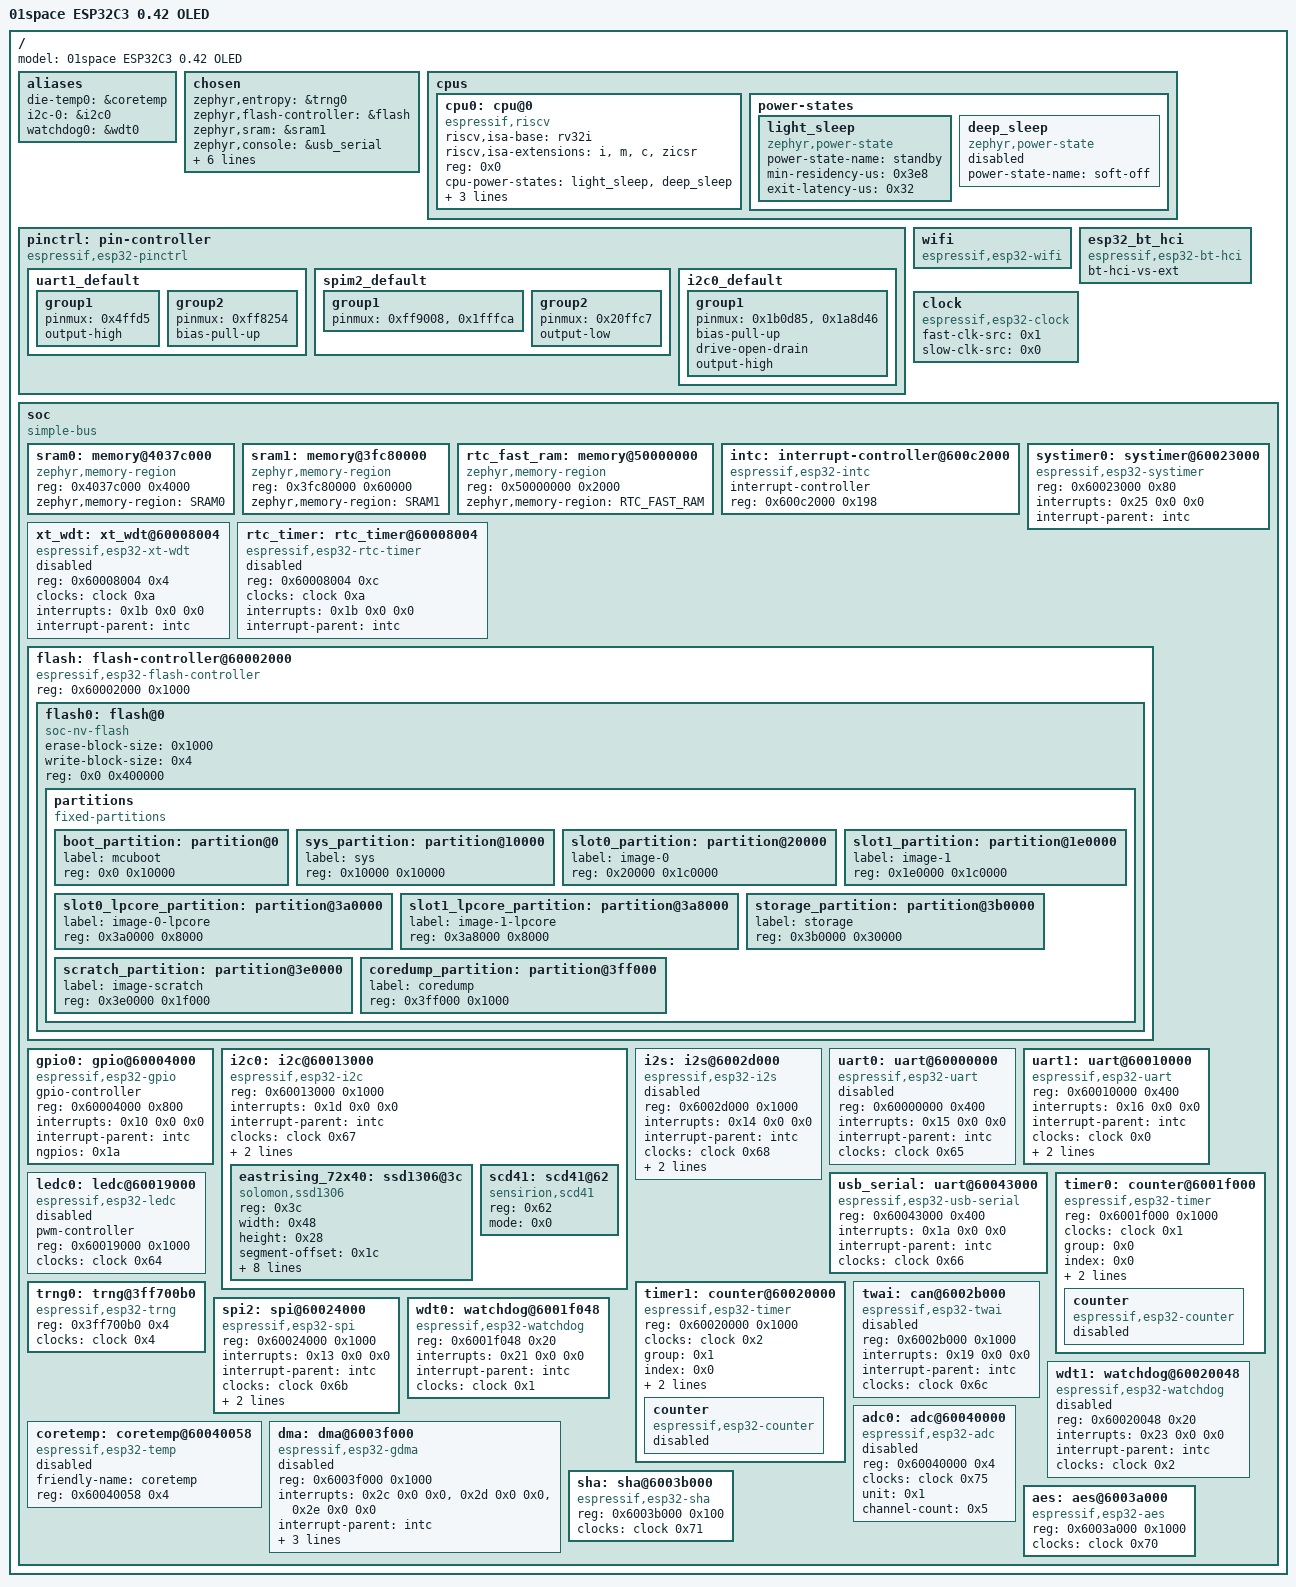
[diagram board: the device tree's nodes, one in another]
/dts-v1/;

/* node '/' defined in zephyr/dts/riscv/espressif/esp32c3/esp32c3_common.dtsi:15 */
/ {
	#address-cells = < 0x1 >;            /* in zephyr/dts/riscv/espressif/esp32c3/esp32c3_common.dtsi:16 */
	#size-cells = < 0x1 >;               /* in zephyr/dts/riscv/espressif/esp32c3/esp32c3_common.dtsi:17 */
	model = "01space ESP32C3 0.42 OLED"; /* in zephyr/boards/01space/esp32c3_042_oled/esp32c3_042_oled.dts:15 */

	/* node '/aliases' defined in zephyr/dts/riscv/espressif/esp32c3/esp32c3_common.dtsi:19 */
	aliases {
		die-temp0 = &coretemp; /* in zephyr/dts/riscv/espressif/esp32c3/esp32c3_common.dtsi:20 */
		i2c-0 = &i2c0;         /* in zephyr/boards/01space/esp32c3_042_oled/esp32c3_042_oled.dts:29 */
		watchdog0 = &wdt0;     /* in zephyr/boards/01space/esp32c3_042_oled/esp32c3_042_oled.dts:30 */
	};

	/* node '/chosen' defined in zephyr/dts/riscv/espressif/esp32c3/esp32c3_common.dtsi:23 */
	chosen {
		zephyr,entropy = &trng0;                  /* in zephyr/dts/riscv/espressif/esp32c3/esp32c3_common.dtsi:25 */
		zephyr,flash-controller = &flash;         /* in zephyr/dts/riscv/espressif/esp32c3/esp32c3_common.dtsi:26 */
		zephyr,sram = &sram1;                     /* in zephyr/boards/01space/esp32c3_042_oled/esp32c3_042_oled.dts:18 */
		zephyr,console = &usb_serial;             /* in zephyr/boards/01space/esp32c3_042_oled/esp32c3_042_oled.dts:19 */
		zephyr,shell-uart = &usb_serial;          /* in zephyr/boards/01space/esp32c3_042_oled/esp32c3_042_oled.dts:20 */
		zephyr,flash = &flash0;                   /* in zephyr/boards/01space/esp32c3_042_oled/esp32c3_042_oled.dts:21 */
		zephyr,code-partition = &slot0_partition; /* in zephyr/boards/01space/esp32c3_042_oled/esp32c3_042_oled.dts:22 */
		zephyr,canbus = &twai;                    /* in zephyr/boards/01space/esp32c3_042_oled/esp32c3_042_oled.dts:23 */
		zephyr,bt-hci = &esp32_bt_hci;            /* in zephyr/boards/01space/esp32c3_042_oled/esp32c3_042_oled.dts:24 */
		zephyr,display = &eastrising_72x40;       /* in zephyr/boards/01space/esp32c3_042_oled/esp32c3_042_oled.dts:25 */
	};

	/* node '/cpus' defined in zephyr/dts/riscv/espressif/esp32c3/esp32c3_common.dtsi:30 */
	cpus {
		#address-cells = < 0x1 >; /* in zephyr/dts/riscv/espressif/esp32c3/esp32c3_common.dtsi:31 */
		#size-cells = < 0x0 >;    /* in zephyr/dts/riscv/espressif/esp32c3/esp32c3_common.dtsi:32 */

		/* node '/cpus/cpu@0' defined in zephyr/dts/riscv/espressif/esp32c3/esp32c3_common.dtsi:34 */
		cpu0: cpu@0 {
			device_type = "cpu";                             /* in zephyr/dts/riscv/espressif/esp32c3/esp32c3_common.dtsi:35 */
			compatible = "espressif,riscv",
			             "riscv";                            /* in zephyr/dts/riscv/espressif/esp32c3/esp32c3_common.dtsi:36 */
			riscv,isa-base = "rv32i";                        /* in zephyr/dts/riscv/espressif/esp32c3/esp32c3_common.dtsi:37 */
			riscv,isa-extensions = "i",
			                       "m",
			                       "c",
			                       "zicsr";                  /* in zephyr/dts/riscv/espressif/esp32c3/esp32c3_common.dtsi:38 */
			reg = < 0x0 >;                                   /* in zephyr/dts/riscv/espressif/esp32c3/esp32c3_common.dtsi:39 */
			cpu-power-states = < &light_sleep &deep_sleep >; /* in zephyr/dts/riscv/espressif/esp32c3/esp32c3_common.dtsi:40 */
			clock-source = < 0x1 >;                          /* in zephyr/dts/riscv/espressif/esp32c3/esp32c3_common.dtsi:41 */
			clock-frequency = < 0x9896800 >;                 /* in zephyr/dts/riscv/espressif/esp32c3/esp32c3_common.dtsi:42 */
			xtal-freq = < 0x2625a00 >;                       /* in zephyr/dts/riscv/espressif/esp32c3/esp32c3_common.dtsi:43 */
		};

		/* node '/cpus/power-states' defined in zephyr/dts/riscv/espressif/esp32c3/esp32c3_common.dtsi:46 */
		power-states {

			/* node '/cpus/power-states/light_sleep' defined in zephyr/dts/riscv/espressif/esp32c3/esp32c3_common.dtsi:47 */
			light_sleep: light_sleep {
				compatible = "zephyr,power-state"; /* in zephyr/dts/riscv/espressif/esp32c3/esp32c3_common.dtsi:48 */
				power-state-name = "standby";      /* in zephyr/dts/riscv/espressif/esp32c3/esp32c3_common.dtsi:49 */
				min-residency-us = < 0x3e8 >;      /* in zephyr/dts/riscv/espressif/esp32c3/esp32c3_common.dtsi:50 */
				exit-latency-us = < 0x32 >;        /* in zephyr/dts/riscv/espressif/esp32c3/esp32c3_common.dtsi:51 */
				phandle = < 0x1 >;                 /* in zephyr/dts/riscv/espressif/esp32c3/esp32c3_common.dtsi:40 */
			};

			/* node '/cpus/power-states/deep_sleep' defined in zephyr/dts/riscv/espressif/esp32c3/esp32c3_common.dtsi:54 */
			deep_sleep: deep_sleep {
				compatible = "zephyr,power-state"; /* in zephyr/dts/riscv/espressif/esp32c3/esp32c3_common.dtsi:58 */
				power-state-name = "soft-off";     /* in zephyr/dts/riscv/espressif/esp32c3/esp32c3_common.dtsi:59 */
				status = "disabled";               /* in zephyr/dts/riscv/espressif/esp32c3/esp32c3_common.dtsi:60 */
				phandle = < 0x2 >;                 /* in zephyr/dts/riscv/espressif/esp32c3/esp32c3_common.dtsi:40 */
			};
		};
	};

	/* node '/pin-controller' defined in zephyr/dts/riscv/espressif/esp32c3/esp32c3_common.dtsi:65 */
	pinctrl: pin-controller {
		compatible = "espressif,esp32-pinctrl"; /* in zephyr/dts/riscv/espressif/esp32c3/esp32c3_common.dtsi:66 */
		status = "okay";                        /* in zephyr/dts/riscv/espressif/esp32c3/esp32c3_common.dtsi:67 */

		/* node '/pin-controller/uart1_default' defined in zephyr/boards/01space/esp32c3_042_oled/esp32c3_042_oled-pinctrl.dtsi:12 */
		uart1_default: uart1_default {
			phandle = < 0x7 >; /* in zephyr/boards/01space/esp32c3_042_oled/esp32c3_042_oled.dts:40 */

			/* node '/pin-controller/uart1_default/group1' defined in zephyr/boards/01space/esp32c3_042_oled/esp32c3_042_oled-pinctrl.dtsi:13 */
			group1 {
				pinmux = < 0x4ffd5 >; /* in zephyr/boards/01space/esp32c3_042_oled/esp32c3_042_oled-pinctrl.dtsi:14 */
				output-high;          /* in zephyr/boards/01space/esp32c3_042_oled/esp32c3_042_oled-pinctrl.dtsi:15 */
			};

			/* node '/pin-controller/uart1_default/group2' defined in zephyr/boards/01space/esp32c3_042_oled/esp32c3_042_oled-pinctrl.dtsi:18 */
			group2 {
				pinmux = < 0xff8254 >; /* in zephyr/boards/01space/esp32c3_042_oled/esp32c3_042_oled-pinctrl.dtsi:19 */
				bias-pull-up;          /* in zephyr/boards/01space/esp32c3_042_oled/esp32c3_042_oled-pinctrl.dtsi:20 */
			};
		};

		/* node '/pin-controller/spim2_default' defined in zephyr/boards/01space/esp32c3_042_oled/esp32c3_042_oled-pinctrl.dtsi:24 */
		spim2_default: spim2_default {
			phandle = < 0x8 >; /* in zephyr/boards/01space/esp32c3_042_oled/esp32c3_042_oled.dts:73 */

			/* node '/pin-controller/spim2_default/group1' defined in zephyr/boards/01space/esp32c3_042_oled/esp32c3_042_oled-pinctrl.dtsi:25 */
			group1 {
				pinmux = < 0xff9008 >,
				         < 0x1fffca >; /* in zephyr/boards/01space/esp32c3_042_oled/esp32c3_042_oled-pinctrl.dtsi:26 */
			};

			/* node '/pin-controller/spim2_default/group2' defined in zephyr/boards/01space/esp32c3_042_oled/esp32c3_042_oled-pinctrl.dtsi:30 */
			group2 {
				pinmux = < 0x20ffc7 >; /* in zephyr/boards/01space/esp32c3_042_oled/esp32c3_042_oled-pinctrl.dtsi:31 */
				output-low;            /* in zephyr/boards/01space/esp32c3_042_oled/esp32c3_042_oled-pinctrl.dtsi:32 */
			};
		};

		/* node '/pin-controller/i2c0_default' defined in zephyr/boards/01space/esp32c3_042_oled/esp32c3_042_oled-pinctrl.dtsi:36 */
		i2c0_default: i2c0_default {
			phandle = < 0x5 >; /* in zephyr/boards/01space/esp32c3_042_oled/esp32c3_042_oled.dts:47 */

			/* node '/pin-controller/i2c0_default/group1' defined in zephyr/boards/01space/esp32c3_042_oled/esp32c3_042_oled-pinctrl.dtsi:37 */
			group1 {
				pinmux = < 0x1b0d85 >,
				         < 0x1a8d46 >; /* in zephyr/boards/01space/esp32c3_042_oled/esp32c3_042_oled-pinctrl.dtsi:38 */
				bias-pull-up;          /* in zephyr/boards/01space/esp32c3_042_oled/esp32c3_042_oled-pinctrl.dtsi:40 */
				drive-open-drain;      /* in zephyr/boards/01space/esp32c3_042_oled/esp32c3_042_oled-pinctrl.dtsi:41 */
				output-high;           /* in zephyr/boards/01space/esp32c3_042_oled/esp32c3_042_oled-pinctrl.dtsi:42 */
			};
		};
	};

	/* node '/wifi' defined in zephyr/dts/riscv/espressif/esp32c3/esp32c3_common.dtsi:70 */
	wifi: wifi {
		compatible = "espressif,esp32-wifi"; /* in zephyr/dts/riscv/espressif/esp32c3/esp32c3_common.dtsi:71 */
		status = "okay";                     /* in zephyr/boards/01space/esp32c3_042_oled/esp32c3_042_oled.dts:102 */
	};

	/* node '/esp32_bt_hci' defined in zephyr/dts/riscv/espressif/esp32c3/esp32c3_common.dtsi:75 */
	esp32_bt_hci: esp32_bt_hci {
		compatible = "espressif,esp32-bt-hci"; /* in zephyr/dts/riscv/espressif/esp32c3/esp32c3_common.dtsi:76 */
		bt-hci-vs-ext;                         /* in zephyr/dts/riscv/espressif/esp32c3/esp32c3_common.dtsi:77 */
		status = "okay";                       /* in zephyr/boards/01space/esp32c3_042_oled/esp32c3_042_oled.dts:106 */
	};

	/* node '/clock' defined in zephyr/dts/riscv/espressif/esp32c3/esp32c3_common.dtsi:81 */
	clock: clock {
		compatible = "espressif,esp32-clock"; /* in zephyr/dts/riscv/espressif/esp32c3/esp32c3_common.dtsi:82 */
		fast-clk-src = < 0x1 >;               /* in zephyr/dts/riscv/espressif/esp32c3/esp32c3_common.dtsi:83 */
		slow-clk-src = < 0x0 >;               /* in zephyr/dts/riscv/espressif/esp32c3/esp32c3_common.dtsi:84 */
		#clock-cells = < 0x1 >;               /* in zephyr/dts/riscv/espressif/esp32c3/esp32c3_common.dtsi:85 */
		status = "okay";                      /* in zephyr/dts/riscv/espressif/esp32c3/esp32c3_common.dtsi:86 */
		phandle = < 0x4 >;                    /* in zephyr/dts/riscv/espressif/esp32c3/esp32c3_common.dtsi:133 */
	};

	/* node '/soc' defined in zephyr/dts/riscv/espressif/esp32c3/esp32c3_common.dtsi:89 */
	soc {
		#address-cells = < 0x1 >;  /* in zephyr/dts/riscv/espressif/esp32c3/esp32c3_common.dtsi:90 */
		#size-cells = < 0x1 >;     /* in zephyr/dts/riscv/espressif/esp32c3/esp32c3_common.dtsi:91 */
		compatible = "simple-bus"; /* in zephyr/dts/riscv/espressif/esp32c3/esp32c3_common.dtsi:92 */
		ranges;                    /* in zephyr/dts/riscv/espressif/esp32c3/esp32c3_common.dtsi:93 */

		/* node '/soc/memory@4037c000' defined in zephyr/dts/riscv/espressif/esp32c3/esp32c3_common.dtsi:95 */
		sram0: memory@4037c000 {
			compatible = "zephyr,memory-region",
			             "mmio-sram";            /* in zephyr/dts/riscv/espressif/esp32c3/esp32c3_common.dtsi:96 */
			reg = < 0x4037c000 0x4000 >;         /* in zephyr/dts/riscv/espressif/esp32c3/esp32c3_common.dtsi:97 */
			zephyr,memory-region = "SRAM0";      /* in zephyr/dts/riscv/espressif/esp32c3/esp32c3_common.dtsi:98 */
		};

		/* node '/soc/memory@3fc80000' defined in zephyr/dts/riscv/espressif/esp32c3/esp32c3_common.dtsi:101 */
		sram1: memory@3fc80000 {
			compatible = "zephyr,memory-region",
			             "mmio-sram";            /* in zephyr/dts/riscv/espressif/esp32c3/esp32c3_common.dtsi:102 */
			reg = < 0x3fc80000 0x60000 >;        /* in zephyr/dts/riscv/espressif/esp32c3/esp32c3_common.dtsi:103 */
			zephyr,memory-region = "SRAM1";      /* in zephyr/dts/riscv/espressif/esp32c3/esp32c3_common.dtsi:104 */
		};

		/* node '/soc/memory@50000000' defined in zephyr/dts/riscv/espressif/esp32c3/esp32c3_common.dtsi:107 */
		rtc_fast_ram: memory@50000000 {
			compatible = "zephyr,memory-region",
			             "mmio-sram";              /* in zephyr/dts/riscv/espressif/esp32c3/esp32c3_common.dtsi:108 */
			reg = < 0x50000000 0x2000 >;           /* in zephyr/dts/riscv/espressif/esp32c3/esp32c3_common.dtsi:109 */
			zephyr,memory-region = "RTC_FAST_RAM"; /* in zephyr/dts/riscv/espressif/esp32c3/esp32c3_common.dtsi:110 */
		};

		/* node '/soc/interrupt-controller@600c2000' defined in zephyr/dts/riscv/espressif/esp32c3/esp32c3_common.dtsi:113 */
		intc: interrupt-controller@600c2000 {
			compatible = "espressif,esp32-intc"; /* in zephyr/dts/riscv/espressif/esp32c3/esp32c3_common.dtsi:114 */
			#address-cells = < 0x0 >;            /* in zephyr/dts/riscv/espressif/esp32c3/esp32c3_common.dtsi:115 */
			#interrupt-cells = < 0x3 >;          /* in zephyr/dts/riscv/espressif/esp32c3/esp32c3_common.dtsi:116 */
			interrupt-controller;                /* in zephyr/dts/riscv/espressif/esp32c3/esp32c3_common.dtsi:117 */
			reg = < 0x600c2000 0x198 >;          /* in zephyr/dts/riscv/espressif/esp32c3/esp32c3_common.dtsi:118 */
			status = "okay";                     /* in zephyr/dts/riscv/espressif/esp32c3/esp32c3_common.dtsi:119 */
			phandle = < 0x3 >;                   /* in zephyr/dts/riscv/espressif/esp32c3/esp32c3_common.dtsi:126 */
		};

		/* node '/soc/systimer@60023000' defined in zephyr/dts/riscv/espressif/esp32c3/esp32c3_common.dtsi:122 */
		systimer0: systimer@60023000 {
			compatible = "espressif,esp32-systimer"; /* in zephyr/dts/riscv/espressif/esp32c3/esp32c3_common.dtsi:123 */
			reg = < 0x60023000 0x80 >;               /* in zephyr/dts/riscv/espressif/esp32c3/esp32c3_common.dtsi:124 */
			interrupts = < 0x25 0x0 0x0 >;           /* in zephyr/dts/riscv/espressif/esp32c3/esp32c3_common.dtsi:125 */
			interrupt-parent = < &intc >;            /* in zephyr/dts/riscv/espressif/esp32c3/esp32c3_common.dtsi:126 */
			status = "okay";                         /* in zephyr/dts/riscv/espressif/esp32c3/esp32c3_common.dtsi:127 */
		};

		/* node '/soc/xt_wdt@60008004' defined in zephyr/dts/riscv/espressif/esp32c3/esp32c3_common.dtsi:130 */
		xt_wdt: xt_wdt@60008004 {
			compatible = "espressif,esp32-xt-wdt"; /* in zephyr/dts/riscv/espressif/esp32c3/esp32c3_common.dtsi:131 */
			reg = < 0x60008004 0x4 >;              /* in zephyr/dts/riscv/espressif/esp32c3/esp32c3_common.dtsi:132 */
			clocks = < &clock 0xa >;               /* in zephyr/dts/riscv/espressif/esp32c3/esp32c3_common.dtsi:133 */
			interrupts = < 0x1b 0x0 0x0 >;         /* in zephyr/dts/riscv/espressif/esp32c3/esp32c3_common.dtsi:134 */
			interrupt-parent = < &intc >;          /* in zephyr/dts/riscv/espressif/esp32c3/esp32c3_common.dtsi:135 */
			status = "disabled";                   /* in zephyr/dts/riscv/espressif/esp32c3/esp32c3_common.dtsi:136 */
		};

		/* node '/soc/rtc_timer@60008004' defined in zephyr/dts/riscv/espressif/esp32c3/esp32c3_common.dtsi:139 */
		rtc_timer: rtc_timer@60008004 {
			reg = < 0x60008004 0xc >;                 /* in zephyr/dts/riscv/espressif/esp32c3/esp32c3_common.dtsi:140 */
			compatible = "espressif,esp32-rtc-timer"; /* in zephyr/dts/riscv/espressif/esp32c3/esp32c3_common.dtsi:141 */
			clocks = < &clock 0xa >;                  /* in zephyr/dts/riscv/espressif/esp32c3/esp32c3_common.dtsi:142 */
			interrupts = < 0x1b 0x0 0x0 >;            /* in zephyr/dts/riscv/espressif/esp32c3/esp32c3_common.dtsi:143 */
			interrupt-parent = < &intc >;             /* in zephyr/dts/riscv/espressif/esp32c3/esp32c3_common.dtsi:144 */
			status = "disabled";                      /* in zephyr/dts/riscv/espressif/esp32c3/esp32c3_common.dtsi:145 */
		};

		/* node '/soc/flash-controller@60002000' defined in zephyr/dts/riscv/espressif/esp32c3/esp32c3_common.dtsi:148 */
		flash: flash-controller@60002000 {
			compatible = "espressif,esp32-flash-controller"; /* in zephyr/dts/riscv/espressif/esp32c3/esp32c3_common.dtsi:149 */
			reg = < 0x60002000 0x1000 >;                     /* in zephyr/dts/riscv/espressif/esp32c3/esp32c3_common.dtsi:150 */
			#address-cells = < 0x1 >;                        /* in zephyr/dts/riscv/espressif/esp32c3/esp32c3_common.dtsi:152 */
			#size-cells = < 0x1 >;                           /* in zephyr/dts/riscv/espressif/esp32c3/esp32c3_common.dtsi:153 */

			/* node '/soc/flash-controller@60002000/flash@0' defined in zephyr/dts/riscv/espressif/esp32c3/esp32c3_common.dtsi:155 */
			flash0: flash@0 {
				compatible = "soc-nv-flash";   /* in zephyr/dts/riscv/espressif/esp32c3/esp32c3_common.dtsi:156 */
				erase-block-size = < 0x1000 >; /* in zephyr/dts/riscv/espressif/esp32c3/esp32c3_common.dtsi:157 */
				write-block-size = < 0x4 >;    /* in zephyr/dts/riscv/espressif/esp32c3/esp32c3_common.dtsi:158 */
				reg = < 0x0 0x400000 >;        /* in zephyr/dts/riscv/espressif/esp32c3/esp32c3_fx4.dtsi:11 */

				/* node '/soc/flash-controller@60002000/flash@0/partitions' defined in zephyr/dts/vendor/espressif/partitions_0x0_default_4M.dtsi:8 */
				partitions {
					compatible = "fixed-partitions"; /* in zephyr/dts/vendor/espressif/partitions_0x0_default_4M.dtsi:9 */
					#address-cells = < 0x1 >;        /* in zephyr/dts/vendor/espressif/partitions_0x0_default_4M.dtsi:10 */
					#size-cells = < 0x1 >;           /* in zephyr/dts/vendor/espressif/partitions_0x0_default_4M.dtsi:11 */

					/* node '/soc/flash-controller@60002000/flash@0/partitions/partition@0' defined in zephyr/dts/vendor/espressif/partitions_0x0_default_4M.dtsi:13 */
					boot_partition: partition@0 {
						label = "mcuboot";     /* in zephyr/dts/vendor/espressif/partitions_0x0_default_4M.dtsi:14 */
						reg = < 0x0 0x10000 >; /* in zephyr/dts/vendor/espressif/partitions_0x0_default_4M.dtsi:15 */
					};

					/* node '/soc/flash-controller@60002000/flash@0/partitions/partition@10000' defined in zephyr/dts/vendor/espressif/partitions_0x0_default_4M.dtsi:18 */
					sys_partition: partition@10000 {
						label = "sys";             /* in zephyr/dts/vendor/espressif/partitions_0x0_default_4M.dtsi:19 */
						reg = < 0x10000 0x10000 >; /* in zephyr/dts/vendor/espressif/partitions_0x0_default_4M.dtsi:20 */
					};

					/* node '/soc/flash-controller@60002000/flash@0/partitions/partition@20000' defined in zephyr/dts/vendor/espressif/partitions_0x0_default_4M.dtsi:23 */
					slot0_partition: partition@20000 {
						label = "image-0";          /* in zephyr/dts/vendor/espressif/partitions_0x0_default_4M.dtsi:24 */
						reg = < 0x20000 0x1c0000 >; /* in zephyr/dts/vendor/espressif/partitions_0x0_default_4M.dtsi:25 */
					};

					/* node '/soc/flash-controller@60002000/flash@0/partitions/partition@1e0000' defined in zephyr/dts/vendor/espressif/partitions_0x0_default_4M.dtsi:28 */
					slot1_partition: partition@1e0000 {
						label = "image-1";           /* in zephyr/dts/vendor/espressif/partitions_0x0_default_4M.dtsi:29 */
						reg = < 0x1e0000 0x1c0000 >; /* in zephyr/dts/vendor/espressif/partitions_0x0_default_4M.dtsi:30 */
					};

					/* node '/soc/flash-controller@60002000/flash@0/partitions/partition@3a0000' defined in zephyr/dts/vendor/espressif/partitions_0x0_default_4M.dtsi:33 */
					slot0_lpcore_partition: partition@3a0000 {
						label = "image-0-lpcore";  /* in zephyr/dts/vendor/espressif/partitions_0x0_default_4M.dtsi:34 */
						reg = < 0x3a0000 0x8000 >; /* in zephyr/dts/vendor/espressif/partitions_0x0_default_4M.dtsi:35 */
					};

					/* node '/soc/flash-controller@60002000/flash@0/partitions/partition@3a8000' defined in zephyr/dts/vendor/espressif/partitions_0x0_default_4M.dtsi:38 */
					slot1_lpcore_partition: partition@3a8000 {
						label = "image-1-lpcore";  /* in zephyr/dts/vendor/espressif/partitions_0x0_default_4M.dtsi:39 */
						reg = < 0x3a8000 0x8000 >; /* in zephyr/dts/vendor/espressif/partitions_0x0_default_4M.dtsi:40 */
					};

					/* node '/soc/flash-controller@60002000/flash@0/partitions/partition@3b0000' defined in zephyr/dts/vendor/espressif/partitions_0x0_default_4M.dtsi:43 */
					storage_partition: partition@3b0000 {
						label = "storage";          /* in zephyr/dts/vendor/espressif/partitions_0x0_default_4M.dtsi:44 */
						reg = < 0x3b0000 0x30000 >; /* in zephyr/dts/vendor/espressif/partitions_0x0_default_4M.dtsi:45 */
					};

					/* node '/soc/flash-controller@60002000/flash@0/partitions/partition@3e0000' defined in zephyr/dts/vendor/espressif/partitions_0x0_default_4M.dtsi:48 */
					scratch_partition: partition@3e0000 {
						label = "image-scratch";    /* in zephyr/dts/vendor/espressif/partitions_0x0_default_4M.dtsi:49 */
						reg = < 0x3e0000 0x1f000 >; /* in zephyr/dts/vendor/espressif/partitions_0x0_default_4M.dtsi:50 */
					};

					/* node '/soc/flash-controller@60002000/flash@0/partitions/partition@3ff000' defined in zephyr/dts/vendor/espressif/partitions_0x0_default_4M.dtsi:53 */
					coredump_partition: partition@3ff000 {
						label = "coredump";        /* in zephyr/dts/vendor/espressif/partitions_0x0_default_4M.dtsi:54 */
						reg = < 0x3ff000 0x1000 >; /* in zephyr/dts/vendor/espressif/partitions_0x0_default_4M.dtsi:55 */
					};
				};
			};
		};

		/* node '/soc/gpio@60004000' defined in zephyr/dts/riscv/espressif/esp32c3/esp32c3_common.dtsi:163 */
		gpio0: gpio@60004000 {
			compatible = "espressif,esp32-gpio"; /* in zephyr/dts/riscv/espressif/esp32c3/esp32c3_common.dtsi:164 */
			gpio-controller;                     /* in zephyr/dts/riscv/espressif/esp32c3/esp32c3_common.dtsi:165 */
			#gpio-cells = < 0x2 >;               /* in zephyr/dts/riscv/espressif/esp32c3/esp32c3_common.dtsi:166 */
			reg = < 0x60004000 0x800 >;          /* in zephyr/dts/riscv/espressif/esp32c3/esp32c3_common.dtsi:167 */
			interrupts = < 0x10 0x0 0x0 >;       /* in zephyr/dts/riscv/espressif/esp32c3/esp32c3_common.dtsi:168 */
			interrupt-parent = < &intc >;        /* in zephyr/dts/riscv/espressif/esp32c3/esp32c3_common.dtsi:169 */
			ngpios = < 0x1a >;                   /* in zephyr/dts/riscv/espressif/esp32c3/esp32c3_common.dtsi:175 */
			status = "okay";                     /* in zephyr/boards/01space/esp32c3_042_oled/esp32c3_042_oled.dts:86 */
		};

		/* node '/soc/i2c@60013000' defined in zephyr/dts/riscv/espressif/esp32c3/esp32c3_common.dtsi:178 */
		i2c0: i2c@60013000 {
			compatible = "espressif,esp32-i2c"; /* in zephyr/dts/riscv/espressif/esp32c3/esp32c3_common.dtsi:179 */
			#address-cells = < 0x1 >;           /* in zephyr/dts/riscv/espressif/esp32c3/esp32c3_common.dtsi:180 */
			#size-cells = < 0x0 >;              /* in zephyr/dts/riscv/espressif/esp32c3/esp32c3_common.dtsi:181 */
			reg = < 0x60013000 0x1000 >;        /* in zephyr/dts/riscv/espressif/esp32c3/esp32c3_common.dtsi:182 */
			interrupts = < 0x1d 0x0 0x0 >;      /* in zephyr/dts/riscv/espressif/esp32c3/esp32c3_common.dtsi:183 */
			interrupt-parent = < &intc >;       /* in zephyr/dts/riscv/espressif/esp32c3/esp32c3_common.dtsi:184 */
			clocks = < &clock 0x67 >;           /* in zephyr/dts/riscv/espressif/esp32c3/esp32c3_common.dtsi:185 */
			clock-frequency = < 0x186a0 >;      /* in zephyr/boards/01space/esp32c3_042_oled/esp32c3_042_oled.dts:46 */
			pinctrl-0 = < &i2c0_default >;      /* in zephyr/boards/01space/esp32c3_042_oled/esp32c3_042_oled.dts:47 */
			pinctrl-names = "default";          /* in zephyr/boards/01space/esp32c3_042_oled/esp32c3_042_oled.dts:48 */
			status = "okay";                    /* in zephyr/samples/ESP32_C3_SCD41/app.overlay:4 */

			/* node '/soc/i2c@60013000/ssd1306@3c' defined in zephyr/boards/01space/esp32c3_042_oled/esp32c3_042_oled.dts:50 */
			eastrising_72x40: ssd1306@3c {
				compatible = "solomon,ssd1306"; /* in zephyr/boards/01space/esp32c3_042_oled/esp32c3_042_oled.dts:51 */
				reg = < 0x3c >;                 /* in zephyr/boards/01space/esp32c3_042_oled/esp32c3_042_oled.dts:52 */
				width = < 0x48 >;               /* in zephyr/boards/01space/esp32c3_042_oled/esp32c3_042_oled.dts:54 */
				height = < 0x28 >;              /* in zephyr/boards/01space/esp32c3_042_oled/esp32c3_042_oled.dts:55 */
				segment-offset = < 0x1c >;      /* in zephyr/boards/01space/esp32c3_042_oled/esp32c3_042_oled.dts:57 */
				page-offset = < 0x0 >;          /* in zephyr/boards/01space/esp32c3_042_oled/esp32c3_042_oled.dts:58 */
				display-offset = < 0x0 >;       /* in zephyr/boards/01space/esp32c3_042_oled/esp32c3_042_oled.dts:59 */
				multiplex-ratio = < 0x27 >;     /* in zephyr/boards/01space/esp32c3_042_oled/esp32c3_042_oled.dts:60 */
				prechargep = < 0x22 >;          /* in zephyr/boards/01space/esp32c3_042_oled/esp32c3_042_oled.dts:61 */
				ready-time-ms = < 0xa >;        /* in zephyr/boards/01space/esp32c3_042_oled/esp32c3_042_oled.dts:62 */
				segment-remap;                  /* in zephyr/boards/01space/esp32c3_042_oled/esp32c3_042_oled.dts:63 */
				com-invdir;                     /* in zephyr/boards/01space/esp32c3_042_oled/esp32c3_042_oled.dts:64 */
				use-internal-iref;              /* in zephyr/boards/01space/esp32c3_042_oled/esp32c3_042_oled.dts:65 */
			};

			/* node '/soc/i2c@60013000/scd41@62' defined in zephyr/samples/ESP32_C3_SCD41/app.overlay:5 */
			scd41: scd41@62 {
				compatible = "sensirion,scd41"; /* in zephyr/samples/ESP32_C3_SCD41/app.overlay:6 */
				reg = < 0x62 >;                 /* in zephyr/samples/ESP32_C3_SCD41/app.overlay:7 */
				mode = < 0x0 >;                 /* in zephyr/samples/ESP32_C3_SCD41/app.overlay:8 */
			};
		};

		/* node '/soc/i2s@6002d000' defined in zephyr/dts/riscv/espressif/esp32c3/esp32c3_common.dtsi:189 */
		i2s: i2s@6002d000 {
			compatible = "espressif,esp32-i2s"; /* in zephyr/dts/riscv/espressif/esp32c3/esp32c3_common.dtsi:190 */
			#address-cells = < 0x1 >;           /* in zephyr/dts/riscv/espressif/esp32c3/esp32c3_common.dtsi:191 */
			#size-cells = < 0x0 >;              /* in zephyr/dts/riscv/espressif/esp32c3/esp32c3_common.dtsi:192 */
			reg = < 0x6002d000 0x1000 >;        /* in zephyr/dts/riscv/espressif/esp32c3/esp32c3_common.dtsi:193 */
			interrupts = < 0x14 0x0 0x0 >;      /* in zephyr/dts/riscv/espressif/esp32c3/esp32c3_common.dtsi:194 */
			interrupt-parent = < &intc >;       /* in zephyr/dts/riscv/espressif/esp32c3/esp32c3_common.dtsi:195 */
			clocks = < &clock 0x68 >;           /* in zephyr/dts/riscv/espressif/esp32c3/esp32c3_common.dtsi:196 */
			dmas = < &dma 0x2 >,
			       < &dma 0x3 >;                /* in zephyr/dts/riscv/espressif/esp32c3/esp32c3_common.dtsi:197 */
			dma-names = "rx",
			            "tx";                   /* in zephyr/dts/riscv/espressif/esp32c3/esp32c3_common.dtsi:198 */
			unit = < 0x0 >;                     /* in zephyr/dts/riscv/espressif/esp32c3/esp32c3_common.dtsi:199 */
			status = "disabled";                /* in zephyr/dts/riscv/espressif/esp32c3/esp32c3_common.dtsi:200 */
		};

		/* node '/soc/uart@60000000' defined in zephyr/dts/riscv/espressif/esp32c3/esp32c3_common.dtsi:203 */
		uart0: uart@60000000 {
			compatible = "espressif,esp32-uart"; /* in zephyr/dts/riscv/espressif/esp32c3/esp32c3_common.dtsi:204 */
			reg = < 0x60000000 0x400 >;          /* in zephyr/dts/riscv/espressif/esp32c3/esp32c3_common.dtsi:205 */
			status = "disabled";                 /* in zephyr/dts/riscv/espressif/esp32c3/esp32c3_common.dtsi:206 */
			interrupts = < 0x15 0x0 0x0 >;       /* in zephyr/dts/riscv/espressif/esp32c3/esp32c3_common.dtsi:207 */
			interrupt-parent = < &intc >;        /* in zephyr/dts/riscv/espressif/esp32c3/esp32c3_common.dtsi:208 */
			clocks = < &clock 0x65 >;            /* in zephyr/dts/riscv/espressif/esp32c3/esp32c3_common.dtsi:209 */
		};

		/* node '/soc/uart@60010000' defined in zephyr/dts/riscv/espressif/esp32c3/esp32c3_common.dtsi:212 */
		uart1: uart@60010000 {
			compatible = "espressif,esp32-uart"; /* in zephyr/dts/riscv/espressif/esp32c3/esp32c3_common.dtsi:213 */
			reg = < 0x60010000 0x400 >;          /* in zephyr/dts/riscv/espressif/esp32c3/esp32c3_common.dtsi:214 */
			interrupts = < 0x16 0x0 0x0 >;       /* in zephyr/dts/riscv/espressif/esp32c3/esp32c3_common.dtsi:216 */
			interrupt-parent = < &intc >;        /* in zephyr/dts/riscv/espressif/esp32c3/esp32c3_common.dtsi:217 */
			clocks = < &clock 0x0 >;             /* in zephyr/dts/riscv/espressif/esp32c3/esp32c3_common.dtsi:218 */
			status = "okay";                     /* in zephyr/boards/01space/esp32c3_042_oled/esp32c3_042_oled.dts:38 */
			current-speed = < 0x1c200 >;         /* in zephyr/boards/01space/esp32c3_042_oled/esp32c3_042_oled.dts:39 */
			pinctrl-0 = < &uart1_default >;      /* in zephyr/boards/01space/esp32c3_042_oled/esp32c3_042_oled.dts:40 */
			pinctrl-names = "default";           /* in zephyr/boards/01space/esp32c3_042_oled/esp32c3_042_oled.dts:41 */
		};

		/* node '/soc/ledc@60019000' defined in zephyr/dts/riscv/espressif/esp32c3/esp32c3_common.dtsi:222 */
		ledc0: ledc@60019000 {
			compatible = "espressif,esp32-ledc"; /* in zephyr/dts/riscv/espressif/esp32c3/esp32c3_common.dtsi:223 */
			pwm-controller;                      /* in zephyr/dts/riscv/espressif/esp32c3/esp32c3_common.dtsi:224 */
			#pwm-cells = < 0x3 >;                /* in zephyr/dts/riscv/espressif/esp32c3/esp32c3_common.dtsi:225 */
			reg = < 0x60019000 0x1000 >;         /* in zephyr/dts/riscv/espressif/esp32c3/esp32c3_common.dtsi:226 */
			clocks = < &clock 0x64 >;            /* in zephyr/dts/riscv/espressif/esp32c3/esp32c3_common.dtsi:227 */
			status = "disabled";                 /* in zephyr/dts/riscv/espressif/esp32c3/esp32c3_common.dtsi:228 */
		};

		/* node '/soc/uart@60043000' defined in zephyr/dts/riscv/espressif/esp32c3/esp32c3_common.dtsi:231 */
		usb_serial: uart@60043000 {
			compatible = "espressif,esp32-usb-serial"; /* in zephyr/dts/riscv/espressif/esp32c3/esp32c3_common.dtsi:232 */
			reg = < 0x60043000 0x400 >;                /* in zephyr/dts/riscv/espressif/esp32c3/esp32c3_common.dtsi:233 */
			interrupts = < 0x1a 0x0 0x0 >;             /* in zephyr/dts/riscv/espressif/esp32c3/esp32c3_common.dtsi:235 */
			interrupt-parent = < &intc >;              /* in zephyr/dts/riscv/espressif/esp32c3/esp32c3_common.dtsi:236 */
			clocks = < &clock 0x66 >;                  /* in zephyr/dts/riscv/espressif/esp32c3/esp32c3_common.dtsi:237 */
			status = "okay";                           /* in zephyr/boards/01space/esp32c3_042_oled/esp32c3_042_oled.dts:78 */
		};

		/* node '/soc/counter@6001f000' defined in zephyr/dts/riscv/espressif/esp32c3/esp32c3_common.dtsi:240 */
		timer0: counter@6001f000 {
			compatible = "espressif,esp32-timer"; /* in zephyr/dts/riscv/espressif/esp32c3/esp32c3_common.dtsi:241 */
			reg = < 0x6001f000 0x1000 >;          /* in zephyr/dts/riscv/espressif/esp32c3/esp32c3_common.dtsi:242 */
			clocks = < &clock 0x1 >;              /* in zephyr/dts/riscv/espressif/esp32c3/esp32c3_common.dtsi:243 */
			group = < 0x0 >;                      /* in zephyr/dts/riscv/espressif/esp32c3/esp32c3_common.dtsi:244 */
			index = < 0x0 >;                      /* in zephyr/dts/riscv/espressif/esp32c3/esp32c3_common.dtsi:245 */
			interrupts = < 0x20 0x0 0x0 >;        /* in zephyr/dts/riscv/espressif/esp32c3/esp32c3_common.dtsi:246 */
			interrupt-parent = < &intc >;         /* in zephyr/dts/riscv/espressif/esp32c3/esp32c3_common.dtsi:247 */
			status = "okay";                      /* in zephyr/boards/01space/esp32c3_042_oled/esp32c3_042_oled.dts:94 */

			/* node '/soc/counter@6001f000/counter' defined in zephyr/dts/riscv/espressif/esp32c3/esp32c3_common.dtsi:250 */
			counter {
				compatible = "espressif,esp32-counter"; /* in zephyr/dts/riscv/espressif/esp32c3/esp32c3_common.dtsi:251 */
				status = "disabled";                    /* in zephyr/dts/riscv/espressif/esp32c3/esp32c3_common.dtsi:252 */
			};
		};

		/* node '/soc/counter@60020000' defined in zephyr/dts/riscv/espressif/esp32c3/esp32c3_common.dtsi:256 */
		timer1: counter@60020000 {
			compatible = "espressif,esp32-timer"; /* in zephyr/dts/riscv/espressif/esp32c3/esp32c3_common.dtsi:257 */
			reg = < 0x60020000 0x1000 >;          /* in zephyr/dts/riscv/espressif/esp32c3/esp32c3_common.dtsi:258 */
			clocks = < &clock 0x2 >;              /* in zephyr/dts/riscv/espressif/esp32c3/esp32c3_common.dtsi:259 */
			group = < 0x1 >;                      /* in zephyr/dts/riscv/espressif/esp32c3/esp32c3_common.dtsi:260 */
			index = < 0x0 >;                      /* in zephyr/dts/riscv/espressif/esp32c3/esp32c3_common.dtsi:261 */
			interrupts = < 0x22 0x0 0x0 >;        /* in zephyr/dts/riscv/espressif/esp32c3/esp32c3_common.dtsi:262 */
			interrupt-parent = < &intc >;         /* in zephyr/dts/riscv/espressif/esp32c3/esp32c3_common.dtsi:263 */
			status = "okay";                      /* in zephyr/boards/01space/esp32c3_042_oled/esp32c3_042_oled.dts:98 */

			/* node '/soc/counter@60020000/counter' defined in zephyr/dts/riscv/espressif/esp32c3/esp32c3_common.dtsi:266 */
			counter {
				compatible = "espressif,esp32-counter"; /* in zephyr/dts/riscv/espressif/esp32c3/esp32c3_common.dtsi:267 */
				status = "disabled";                    /* in zephyr/dts/riscv/espressif/esp32c3/esp32c3_common.dtsi:268 */
			};
		};

		/* node '/soc/trng@3ff700b0' defined in zephyr/dts/riscv/espressif/esp32c3/esp32c3_common.dtsi:272 */
		trng0: trng@3ff700b0 {
			compatible = "espressif,esp32-trng"; /* in zephyr/dts/riscv/espressif/esp32c3/esp32c3_common.dtsi:273 */
			reg = < 0x3ff700b0 0x4 >;            /* in zephyr/dts/riscv/espressif/esp32c3/esp32c3_common.dtsi:274 */
			clocks = < &clock 0x4 >;             /* in zephyr/dts/riscv/espressif/esp32c3/esp32c3_common.dtsi:275 */
			status = "okay";                     /* in zephyr/boards/01space/esp32c3_042_oled/esp32c3_042_oled.dts:82 */
		};

		/* node '/soc/can@6002b000' defined in zephyr/dts/riscv/espressif/esp32c3/esp32c3_common.dtsi:279 */
		twai: can@6002b000 {
			compatible = "espressif,esp32-twai"; /* in zephyr/dts/riscv/espressif/esp32c3/esp32c3_common.dtsi:280 */
			reg = < 0x6002b000 0x1000 >;         /* in zephyr/dts/riscv/espressif/esp32c3/esp32c3_common.dtsi:281 */
			interrupts = < 0x19 0x0 0x0 >;       /* in zephyr/dts/riscv/espressif/esp32c3/esp32c3_common.dtsi:282 */
			interrupt-parent = < &intc >;        /* in zephyr/dts/riscv/espressif/esp32c3/esp32c3_common.dtsi:283 */
			clocks = < &clock 0x6c >;            /* in zephyr/dts/riscv/espressif/esp32c3/esp32c3_common.dtsi:284 */
			status = "disabled";                 /* in zephyr/dts/riscv/espressif/esp32c3/esp32c3_common.dtsi:285 */
		};

		/* node '/soc/spi@60024000' defined in zephyr/dts/riscv/espressif/esp32c3/esp32c3_common.dtsi:288 */
		spi2: spi@60024000 {
			compatible = "espressif,esp32-spi"; /* in zephyr/dts/riscv/espressif/esp32c3/esp32c3_common.dtsi:289 */
			reg = < 0x60024000 0x1000 >;        /* in zephyr/dts/riscv/espressif/esp32c3/esp32c3_common.dtsi:290 */
			interrupts = < 0x13 0x0 0x0 >;      /* in zephyr/dts/riscv/espressif/esp32c3/esp32c3_common.dtsi:291 */
			interrupt-parent = < &intc >;       /* in zephyr/dts/riscv/espressif/esp32c3/esp32c3_common.dtsi:292 */
			clocks = < &clock 0x6b >;           /* in zephyr/dts/riscv/espressif/esp32c3/esp32c3_common.dtsi:293 */
			dma-host = < 0x0 >;                 /* in zephyr/dts/riscv/espressif/esp32c3/esp32c3_common.dtsi:294 */
			#address-cells = < 0x1 >;           /* in zephyr/boards/01space/esp32c3_042_oled/esp32c3_042_oled.dts:70 */
			#size-cells = < 0x0 >;              /* in zephyr/boards/01space/esp32c3_042_oled/esp32c3_042_oled.dts:71 */
			status = "okay";                    /* in zephyr/boards/01space/esp32c3_042_oled/esp32c3_042_oled.dts:72 */
			pinctrl-0 = < &spim2_default >;     /* in zephyr/boards/01space/esp32c3_042_oled/esp32c3_042_oled.dts:73 */
			pinctrl-names = "default";          /* in zephyr/boards/01space/esp32c3_042_oled/esp32c3_042_oled.dts:74 */
		};

		/* node '/soc/watchdog@6001f048' defined in zephyr/dts/riscv/espressif/esp32c3/esp32c3_common.dtsi:298 */
		wdt0: watchdog@6001f048 {
			compatible = "espressif,esp32-watchdog"; /* in zephyr/dts/riscv/espressif/esp32c3/esp32c3_common.dtsi:299 */
			reg = < 0x6001f048 0x20 >;               /* in zephyr/dts/riscv/espressif/esp32c3/esp32c3_common.dtsi:300 */
			interrupts = < 0x21 0x0 0x0 >;           /* in zephyr/dts/riscv/espressif/esp32c3/esp32c3_common.dtsi:301 */
			interrupt-parent = < &intc >;            /* in zephyr/dts/riscv/espressif/esp32c3/esp32c3_common.dtsi:302 */
			clocks = < &clock 0x1 >;                 /* in zephyr/dts/riscv/espressif/esp32c3/esp32c3_common.dtsi:303 */
			status = "okay";                         /* in zephyr/boards/01space/esp32c3_042_oled/esp32c3_042_oled.dts:90 */
		};

		/* node '/soc/watchdog@60020048' defined in zephyr/dts/riscv/espressif/esp32c3/esp32c3_common.dtsi:307 */
		wdt1: watchdog@60020048 {
			compatible = "espressif,esp32-watchdog"; /* in zephyr/dts/riscv/espressif/esp32c3/esp32c3_common.dtsi:308 */
			reg = < 0x60020048 0x20 >;               /* in zephyr/dts/riscv/espressif/esp32c3/esp32c3_common.dtsi:309 */
			interrupts = < 0x23 0x0 0x0 >;           /* in zephyr/dts/riscv/espressif/esp32c3/esp32c3_common.dtsi:310 */
			interrupt-parent = < &intc >;            /* in zephyr/dts/riscv/espressif/esp32c3/esp32c3_common.dtsi:311 */
			clocks = < &clock 0x2 >;                 /* in zephyr/dts/riscv/espressif/esp32c3/esp32c3_common.dtsi:312 */
			status = "disabled";                     /* in zephyr/dts/riscv/espressif/esp32c3/esp32c3_common.dtsi:313 */
		};

		/* node '/soc/coretemp@60040058' defined in zephyr/dts/riscv/espressif/esp32c3/esp32c3_common.dtsi:316 */
		coretemp: coretemp@60040058 {
			compatible = "espressif,esp32-temp"; /* in zephyr/dts/riscv/espressif/esp32c3/esp32c3_common.dtsi:317 */
			friendly-name = "coretemp";          /* in zephyr/dts/riscv/espressif/esp32c3/esp32c3_common.dtsi:318 */
			reg = < 0x60040058 0x4 >;            /* in zephyr/dts/riscv/espressif/esp32c3/esp32c3_common.dtsi:319 */
			status = "disabled";                 /* in zephyr/dts/riscv/espressif/esp32c3/esp32c3_common.dtsi:320 */
		};

		/* node '/soc/adc@60040000' defined in zephyr/dts/riscv/espressif/esp32c3/esp32c3_common.dtsi:323 */
		adc0: adc@60040000 {
			compatible = "espressif,esp32-adc"; /* in zephyr/dts/riscv/espressif/esp32c3/esp32c3_common.dtsi:324 */
			reg = < 0x60040000 0x4 >;           /* in zephyr/dts/riscv/espressif/esp32c3/esp32c3_common.dtsi:325 */
			clocks = < &clock 0x75 >;           /* in zephyr/dts/riscv/espressif/esp32c3/esp32c3_common.dtsi:326 */
			unit = < 0x1 >;                     /* in zephyr/dts/riscv/espressif/esp32c3/esp32c3_common.dtsi:327 */
			channel-count = < 0x5 >;            /* in zephyr/dts/riscv/espressif/esp32c3/esp32c3_common.dtsi:328 */
			#io-channel-cells = < 0x1 >;        /* in zephyr/dts/riscv/espressif/esp32c3/esp32c3_common.dtsi:329 */
			status = "disabled";                /* in zephyr/dts/riscv/espressif/esp32c3/esp32c3_common.dtsi:330 */
		};

		/* node '/soc/dma@6003f000' defined in zephyr/dts/riscv/espressif/esp32c3/esp32c3_common.dtsi:333 */
		dma: dma@6003f000 {
			compatible = "espressif,esp32-gdma"; /* in zephyr/dts/riscv/espressif/esp32c3/esp32c3_common.dtsi:334 */
			reg = < 0x6003f000 0x1000 >;         /* in zephyr/dts/riscv/espressif/esp32c3/esp32c3_common.dtsi:335 */
			#dma-cells = < 0x1 >;                /* in zephyr/dts/riscv/espressif/esp32c3/esp32c3_common.dtsi:336 */
			interrupts = < 0x2c 0x0 0x0 >,
			             < 0x2d 0x0 0x0 >,
			             < 0x2e 0x0 0x0 >;       /* in zephyr/dts/riscv/espressif/esp32c3/esp32c3_common.dtsi:337 */
			interrupt-parent = < &intc >;        /* in zephyr/dts/riscv/espressif/esp32c3/esp32c3_common.dtsi:340 */
			clocks = < &clock 0x74 >;            /* in zephyr/dts/riscv/espressif/esp32c3/esp32c3_common.dtsi:341 */
			dma-channels = < 0x6 >;              /* in zephyr/dts/riscv/espressif/esp32c3/esp32c3_common.dtsi:342 */
			dma-buf-addr-alignment = < 0x4 >;    /* in zephyr/dts/riscv/espressif/esp32c3/esp32c3_common.dtsi:343 */
			status = "disabled";                 /* in zephyr/dts/riscv/espressif/esp32c3/esp32c3_common.dtsi:344 */
			phandle = < 0x6 >;                   /* in zephyr/dts/riscv/espressif/esp32c3/esp32c3_common.dtsi:197 */
		};

		/* node '/soc/sha@6003b000' defined in zephyr/dts/riscv/espressif/esp32c3/esp32c3_common.dtsi:347 */
		sha: sha@6003b000 {
			compatible = "espressif,esp32-sha"; /* in zephyr/dts/riscv/espressif/esp32c3/esp32c3_common.dtsi:348 */
			reg = < 0x6003b000 0x100 >;         /* in zephyr/dts/riscv/espressif/esp32c3/esp32c3_common.dtsi:349 */
			clocks = < &clock 0x71 >;           /* in zephyr/dts/riscv/espressif/esp32c3/esp32c3_common.dtsi:350 */
			status = "okay";                    /* in zephyr/dts/riscv/espressif/esp32c3/esp32c3_common.dtsi:351 */
		};

		/* node '/soc/aes@6003a000' defined in zephyr/dts/riscv/espressif/esp32c3/esp32c3_common.dtsi:354 */
		aes: aes@6003a000 {
			compatible = "espressif,esp32-aes"; /* in zephyr/dts/riscv/espressif/esp32c3/esp32c3_common.dtsi:355 */
			reg = < 0x6003a000 0x1000 >;        /* in zephyr/dts/riscv/espressif/esp32c3/esp32c3_common.dtsi:356 */
			clocks = < &clock 0x70 >;           /* in zephyr/dts/riscv/espressif/esp32c3/esp32c3_common.dtsi:357 */
			status = "okay";                    /* in zephyr/dts/riscv/espressif/esp32c3/esp32c3_common.dtsi:358 */
		};
	};
};
